# AT32F415xx register map
Vendor: Keil; Series: AT32F415; File version: 1.0
CPU: CM4 r0p1, little endian, no MPU, FPU, 4 interrupt priority bits
Registers are 32-bit, read-write, reset 0x0 unless marked. A register's access mark holds for its fields unless they carry their own. Offsets are from the block's base; [hi:lo] are bit positions; {n}, {i} and the like mark numbered series.

## USB_OTG_GLOBAL — USB on the go full speed
Base 0x50000000
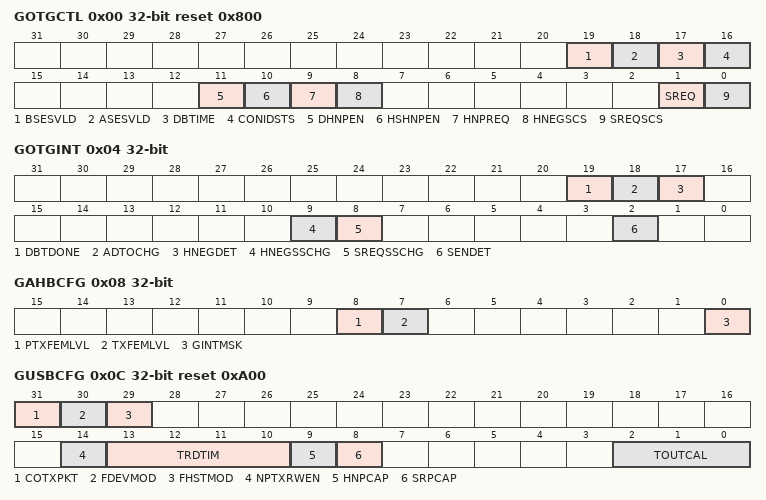
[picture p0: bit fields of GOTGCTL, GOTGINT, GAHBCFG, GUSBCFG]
0x00 GOTGCTL reset 0x800 — OTG_FS control and status register (OTG_FS_GOTGCTL)
  [19] BSESVLD ro — B-session valid
  [18] ASESVLD ro — A-session valid
  [17] DBTIME ro — Long/short debounce time
  [16] CONIDSTS ro — Connector ID status
  [11] DHNPEN — Device HNP enabled
  [10] HSHNPEN — Host set HNP enable
  [9] HNPREQ — HNP request
  [8] HNEGSCS ro — Host negotiation success
  [1] SREQ — Session request
  [0] SREQSCS ro — Session request success
0x04 GOTGINT — OTG_FS interrupt register (OTG_FS_GOTGINT)
  [19] DBTDONE — Debounce done
  [18] ADTOCHG — A-device timeout change
  [17] HNEGDET — Host negotiation detected
  [9] HNEGSSCHG — Host negotiation success status change
  [8] SREQSSCHG — Session request success status change
  [2] SENDET — Session end detected
0x08 GAHBCFG — OTG_FS AHB configuration register (OTG_FS_GAHBCFG)
  [8] PTXFEMLVL — Periodic TxFIFO empty level
  [7] TXFEMLVL — TxFIFO empty level
  [0] GINTMSK — Global interrupt mask
0x0C GUSBCFG reset 0xA00 — OTG_FS USB configuration register (OTG_FS_GUSBCFG)
  [31] COTXPKT — Corrupt Tx packet
  [30] FDEVMOD — Force device mode
  [29] FHSTMOD — Force host mode
  [14] NPTXRWEN — non-periodic TxFIFO rewind enable
  [13:10] TRDTIM — USB turnaround time
  [9] HNPCAP — HNP-capable
  [8] SRPCAP — SRP-capable
  [2:0] TOUTCAL — FS timeout calibration
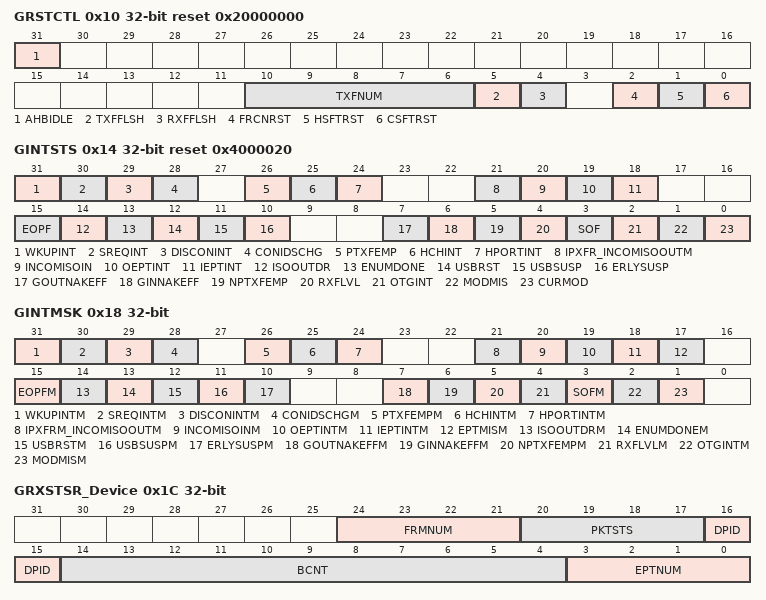
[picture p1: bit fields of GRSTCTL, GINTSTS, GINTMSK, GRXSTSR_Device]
0x10 GRSTCTL reset 0x20000000 — OTG_FS reset register (OTG_FS_GRSTCTL)
  [31] AHBIDLE ro — AHB master idle
  [10:6] TXFNUM — TxFIFO number
  [5] TXFFLSH — TxFIFO flush
  [4] RXFFLSH — RxFIFO flush
  [2] FRCNRST — Host frame counter reset
  [1] HSFTRST — HCLK soft reset
  [0] CSFTRST — Core soft reset
0x14 GINTSTS reset 0x4000020 — OTG_FS core interrupt register (OTG_FS_GINTSTS)
  [31] WKUPINT — Resume/remote wakeup detected interrupt
  [30] SREQINT — Session request/new session detected interrupt
  [29] DISCONINT — Disconnect detected interrupt
  [28] CONIDSCHG — Connector ID status change
  [26] PTXFEMP ro — Periodic TxFIFO empty
  [25] HCHINT ro — Host channels interrupt
  [24] HPORTINT ro — Host port interrupt
  [21] IPXFR_INCOMISOOUTM — Incomplete periodic transfer(Host mode)/Incomplete isochronous OUT transfer(Device mode)
  [20] INCOMISOIN — Incomplete isochronous IN transfer
  [19] OEPTINT ro — OUT endpoint interrupt
  [18] IEPTINT ro — IN endpoint interrupt
  [15] EOPF — End of periodic frame interrupt
  [14] ISOOUTDR — Isochronous OUT packet dropped interrupt
  [13] ENUMDONE — Enumeration done
  [12] USBRST — USB reset
  [11] USBSUSP — USB suspend
  [10] ERLYSUSP — Early suspend
  [7] GOUTNAKEFF ro — Global OUT NAK effective
  [6] GINNAKEFF ro — Global IN non-periodic NAK effective
  [5] NPTXFEMP ro — Non-periodic TxFIFO empty
  [4] RXFLVL ro — RxFIFO non-empty
  [3] SOF — Start of frame
  [2] OTGINT ro — OTG interrupt
  [1] MODMIS — Mode mismatch interrupt
  [0] CURMOD ro — Current mode of operation
0x18 GINTMSK — OTG_FS interrupt mask register (OTG_FS_GINTMSK)
  [31] WKUPINTM — Resume/remote wakeup detected interrupt mask
  [30] SREQINTM — Session request/new session detected interrupt mask
  [29] DISCONINTM — Disconnect detected interrupt mask
  [28] CONIDSCHGM — Connector ID status change mask
  [26] PTXFEMPM — Periodic TxFIFO empty mask
  [25] HCHINTM — Host channels interrupt mask
  [24] HPORTINTM ro — Host port interrupt mask
  [21] IPXFRM_INCOMISOOUTM — Incomplete periodic transfer mask(Host mode)/Incomplete isochronous OUT transfer mask(Device mode)
  [20] INCOMISOINM — Incomplete isochronous IN transfer mask
  [19] OEPTINTM — OUT endpoints interrupt mask
  [18] IEPTINTM — IN endpoints interrupt mask
  [17] EPTMISM — Endpoint mismatch interrupt mask
  [15] EOPFM — End of periodic frame interrupt mask
  [14] ISOOUTDRM — Isochronous OUT packet dropped interrupt mask
  [13] ENUMDONEM — Enumeration done mask
  [12] USBRSTM — USB reset mask
  [11] USBSUSPM — USB suspend mask
  [10] ERLYSUSPM — Early suspend mask
  [7] GOUTNAKEFFM — Global OUT NAK effective mask
  [6] GINNAKEFFM — Global non-periodic IN NAK effective mask
  [5] NPTXFEMPM — Non-periodic TxFIFO empty mask
  [4] RXFLVLM — Receive FIFO non-empty mask
  [3] SOFM — Start of frame mask
  [2] OTGINTM — OTG interrupt mask
  [1] MODMISM — Mode mismatch interrupt mask
0x1C GRXSTSR_Device ro — OTG_FS Receive status debug read(Device mode)
  [24:21] FRMNUM — Frame number
  [20:17] PKTSTS — Packet status
  [16:15] DPID — Data PID
  [14:4] BCNT — Byte count
  [3:0] EPTNUM — Endpoint number
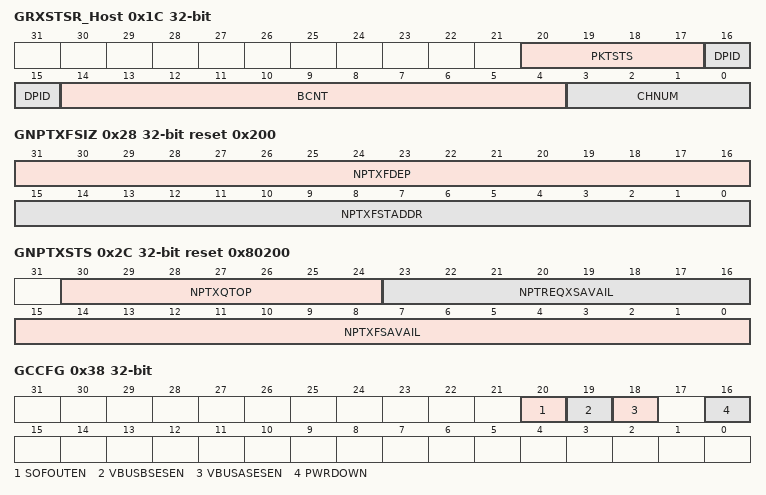
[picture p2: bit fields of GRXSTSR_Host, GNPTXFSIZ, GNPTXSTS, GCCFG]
0x1C GRXSTSR_Host ro (alternate view of GRXSTSR_Device) — OTG_FS Receive status debug read(Host mode)
  [20:17] PKTSTS — Packet status
  [16:15] DPID — Data PID
  [14:4] BCNT — Byte count
  [3:0] CHNUM — Channel number
0x24 GRXFSIZ reset 0x200 — OTG_FS Receive FIFO size register (OTG_FS_GRXFSIZ)
  [15:0] RXFDEP — RxFIFO depth
0x28 GNPTXFSIZ reset 0x200 — OTG_FS non-periodic transmit FIFO size register (Device mode)
  [31:16] NPTXFDEP — Endpoint 0 TxFIFO depth
  [15:0] NPTXFSTADDR — Endpoint 0 transmit RAM start address
0x2C GNPTXSTS ro reset 0x80200 — OTG_FS non-periodic transmit FIFO/queue status register (OTG_FS_GNPTXSTS)
  [30:24] NPTXQTOP — Top of the non-periodic transmit request queue
  [23:16] NPTREQXSAVAIL — Non-periodic transmit request queue space available
  [15:0] NPTXFSAVAIL — Non-periodic TxFIFO space available
0x38 GCCFG — OTG_FS general core configuration register (OTG_FS_GCCFG)
  [20] SOFOUTEN — SOF output enable
  [19] VBUSBSESEN — Enable the VBUS sensing device
  [18] VBUSASESEN — Enable the VBUS sensing device
  [16] PWRDOWN — Power down
0x3C GUID reset 0x1000 — Product ID register
  [31:0] USERID — Product ID field
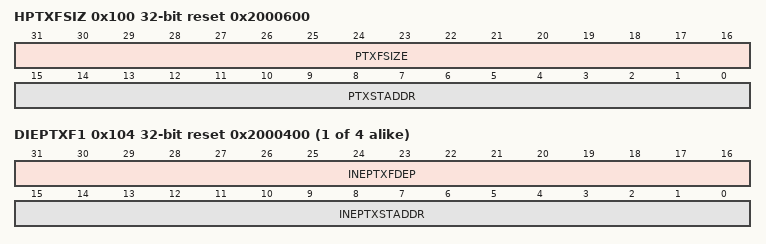
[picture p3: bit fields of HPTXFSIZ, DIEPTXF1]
0x100 HPTXFSIZ reset 0x2000600 — OTG_FS Host periodic transmit FIFO size register (OTG_FS_HPTXFSIZ)
  [31:16] PTXFSIZE — Host periodic TxFIFO depth
  [15:0] PTXSTADDR — Host periodic TxFIFO start address
{0x100+4i} DIEPTXF{i} reset 0x2000400 (i=1..4) — OTG_FS device IN endpoint transmit FIFO size register (OTG_FS_DIEPTXF{i})
  [31:16] INEPTXFDEP — IN endpoint TxFIFO depth
  [15:0] INEPTXSTADDR — IN endpoint FIFO{i} transmit RAM start address
